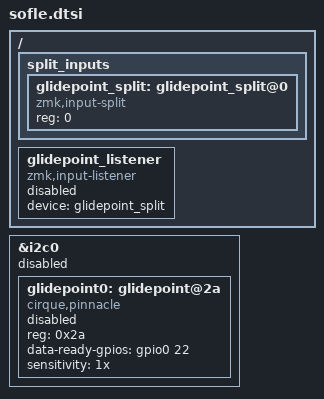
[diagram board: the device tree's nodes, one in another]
&i2c0 {
    status = "disabled";
    glidepoint0: glidepoint@2a {
        compatible = "cirque,pinnacle";
        reg = <0x2a>;
        status = "disabled";
        data-ready-gpios = <&gpio0 22 (GPIO_ACTIVE_HIGH)>;

        sensitivity = "1x";
    };

};

/ {
    split_inputs {
        #address-cells = <1>;
        #size-cells = <0>;

        glidepoint_split: glidepoint_split@0 {
            compatible = "zmk,input-split";
            reg = <0>;
        };
    };

    glidepoint_listener: glidepoint_listener {
        compatible = "zmk,input-listener";
        status = "disabled";
        device = <&glidepoint_split>;
    };
};
